# SAM9X75D5MN0 device description
Architecture: ARM926EJ-S; Family: SAM9; Series: SAM9X7
Registers are 32-bit, read-write, reset 0x0 unless marked. A register's access mark holds for its fields unless they carry their own. Offsets are from the block's base; [hi:lo] are bit positions.

## CLASSD — Audio Class D Amplifier
Instances: CLASSD 0xF003C000
0x00 CLASSD_CR wo reset not defined — Control Register
  [0] SWRST — Software Reset
    0=No effect; 1=Resets the CLASSD simulating a hardware reset
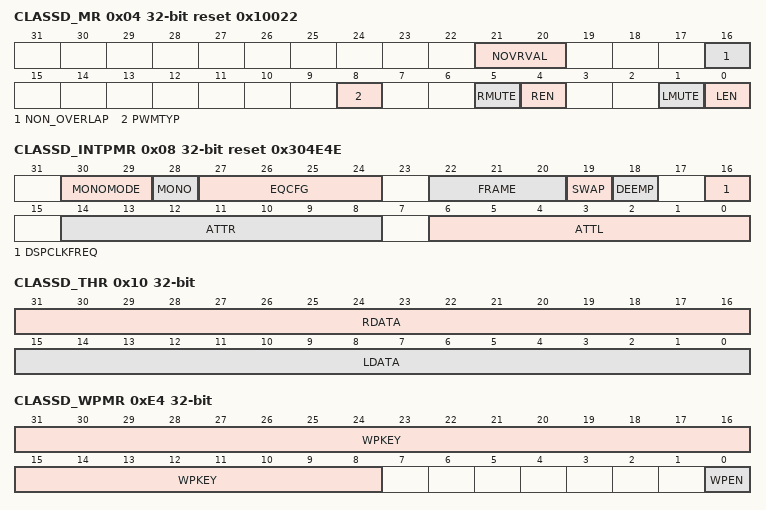
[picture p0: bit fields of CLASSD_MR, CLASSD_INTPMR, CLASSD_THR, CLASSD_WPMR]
0x04 CLASSD_MR reset 0x10022 — Mode Register
  [21:20] NOVRVAL — Non-Overlapping Value
    0=5NS (Non-overlapping time is 5 ns); 1=10NS (Non-overlapping time is 10 ns); 2=15NS (Non-overlapping time is 15 ns); 3=20NS (Non-overlapping time is 20 ns)
  [16] NON_OVERLAP — Non-Overlapping Enable
    0=Non-overlapping circuit is disabled; 1=Non-overlapping circuit is enabled
  [8] PWMTYP — PWM Modulation Type
    0=TRAILING_EDGE (The signal is single-ended.); 1=UNIFORM (The signal is differential.)
  [5] RMUTE — Right Channel Mute
    0=Right channel is unmuted; 1=Right channel is muted
  [4] REN — Right Channel Enable
    0=Right channel is disabled; 1=Right channel is enabled
  [1] LMUTE — Left Channel Mute
    0=Left channel is unmuted; 1=Left channel is muted
  [0] LEN — Left Channel Enable
    0=Left channel is disabled; 1=Left channel is enabled
0x08 CLASSD_INTPMR reset 0x304E4E — Interpolator Mode Register
  [30:29] MONOMODE — Mono Mode Selection
    0=MONOMIX ((left + right) / 2 is sent on both channels); 1=MONOSAT ((left + right) is sent to both channels. If the sum is too high, the result is saturated.); 2=MONOLEFT (THR[15:0] is sent on both left and right channels); 3=MONORIGHT (THR[31:16] is sent on both left and right channels)
  [28] MONO — Mono Signal
    0=DISABLED (The signal is sent stereo to the left and right channels.); 1=ENABLED (The same signal is sent on both left and right channels. The sent signal is defined by the MONOMODE field value.)
  [27:24] EQCFG — Equalization Selection
    0=FLAT (Flat Response); 1=BBOOST12 (Bass boost +12 dB); 2=BBOOST6 (Bass boost +6 dB); 3=BCUT12 (Bass cut -12 dB); 4=BCUT6 (Bass cut -6 dB); 5=MBOOST3 (Medium boost +3 dB); 6=MBOOST8 (Medium boost +8 dB); 7=MCUT3 (Medium cut -3 dB); 8=MCUT8 (Medium cut -8 dB); 9=TBOOST12 (Treble boost +12 dB); 10=TBOOST6 (Treble boost +6 dB); 11=TCUT12 (Treble cut -12 dB); 12=TCUT6 (Treble cut -6 dB)
  [22:20] FRAME — CLASSD Incoming Data Sampling Frequency
    0=FRAME_8K (8 kHz); 1=FRAME_16K (16 kHz); 2=FRAME_32K (32 kHz); 3=FRAME_48K (48 kHz); 4=FRAME_96K (96 kHz); 5=FRAME_22K (22.05 kHz); 6=FRAME_44K (44.1 kHz); 7=FRAME_88K (88.2 kHz)
  [19] SWAP — Swap Left and Right Channels
    0=LEFT_ON_LSB (Left channel is on CLASSD_THR[15:0], right channel is on CLASSD_THR[31:16].); 1=RIGHT_ON_LSB (Right channel is on CLASSD_THR[15:0], left channel is on CLASSD_THR[31:16].)
  [18] DEEMP — Enable De-emphasis Filter
    0=DISABLED (De-emphasis filter is disabled.); 1=ENABLED (De-emphasis filter is enabled.)
  [16] DSPCLKFREQ — DSP Clock Frequency
    0=12M288 (DSP Clock (DSPCLK) is 12.288 MHz.); 1=11M2896 (DSP Clock (DSPCLK) is 11.2896 MHz.)
  [14:8] ATTR — Right Channel Attenuation
  [6:0] ATTL — Left Channel Attenuation
0x0C CLASSD_INTSR ro — Interpolator Status Register
  [0] CFGERR — Configuration Error
    0=The frame and clock configuration are correct; 1=The frame and clock configuration are incorrect (see Section 7.1.1 "Clock Configuration" for information about allowed configurations)
0x10 CLASSD_THR — Transmit Holding Register
  [31:16] RDATA — Right Channel Data
  [15:0] LDATA — Left Channel Data
0x14 CLASSD_IER wo reset not defined (atomic set of CLASSD_IMR) — Interrupt Enable Register
  [0] DATRDY — Data Ready
    0=No effect; 1=Enables the interrupt when the CLASSD is ready to receive a new data to convert
0x18 CLASSD_IDR wo reset not defined (atomic clear of CLASSD_IMR) — Interrupt Disable Register
  [0] DATRDY — Data Ready
    0=No effect; 1=Disables the interrupt when the CLASSD is ready to receive a new data to convert
0x1C CLASSD_IMR — Interrupt Mask Register
  [0] DATRDY — Data Ready
    0=The interrupt is disabled; 1=The interrupt is enabled
0x20 CLASSD_ISR ro — Interrupt Status Register
  [0] DATRDY — Data Ready
    0=CLASSD has not been ready to convert a value since the last read of CLASSD_ISR; 1=CLASSD is ready to convert a value since the last read of CLASSD_ISR
0xE4 CLASSD_WPMR — Write Protection Mode Register
  [31:8] WPKEY — Write Protection Key
    0x434C44=PASSWD (Writing any other value in this field aborts the write operation of the WPEN bit. Always reads as 0.)
  [0] WPEN — Write Protection Enable
    0=Disables the write protection if WPKEY corresponds to 0x434C44 ("CLD" in ASCII); 1=Enables the write protection if WPKEY corresponds to 0x434C44 ("CLD" in ASCII)
